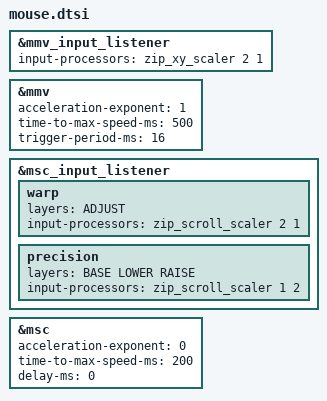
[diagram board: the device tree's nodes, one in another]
/*
     _____        __ _          _   __           _                         _
    /  ___|      / _| |        | | / /          | |                       | |
    \ `--.  ___ | |_| | ___    | |/ /  ___ _   _| |__   ___   __ _ _ __ __| |
     `--. \/ _ \|  _| |/ _ \   |    \ / _ \ | | | '_ \ / _ \ / _` | '__/ _` |
    /\__/ / (_) | | | |  __/   | |\  \  __/ |_| | |_) | (_) | (_| | | | (_| |
    \____/ \___/|_| |_|\___|   \_| \_/\___|\__, |_.__/ \___/ \__,_|_|  \__,_|
                                            __/ |
                                           |___/
*/


#define ZMK_POINTING_DEFAULT_MOVE_VAL 800  // 600
#define ZMK_POINTING_DEFAULT_SCRL_VAL 15   // 10

#include <input/processors.dtsi>
#include <dt-bindings/zmk/pointing.h>
#include <zephyr/dt-bindings/input/input-event-codes.h>

// Mouse movements
&mmv_input_listener { input-processors = <&zip_xy_scaler 2 1>; };

&mmv {
    acceleration-exponent = <1>;
    time-to-max-speed-ms = <500>;
    trigger-period-ms = <16>;
};

// Mouse scroll
&msc_input_listener {
  warp {
    layers = <ADJUST>;
    input-processors = <&zip_scroll_scaler 2 1>;
  };
  precision {
    layers = <BASE LOWER RAISE>;
    input-processors = <&zip_scroll_scaler 1 2>;
  };
};

&msc {
    acceleration-exponent = <0>;      // 0
    time-to-max-speed-ms = <200>;     // 300
    delay-ms = <0>;                   // 0
};

// Handy mouse related definition
#define U_MS_U &mmv MOVE_UP
#define U_MS_D &mmv MOVE_DOWN
#define U_MS_L &mmv MOVE_LEFT
#define U_MS_R &mmv MOVE_RIGHT
#define U_WH_U &msc SCRL_UP
#define U_WH_D &msc SCRL_DOWN
#define U_WH_L &msc SCRL_LEFT
#define U_WH_R &msc SCRL_RIGHT
